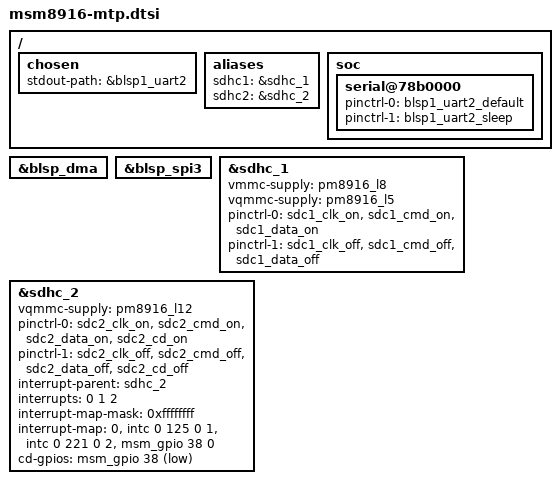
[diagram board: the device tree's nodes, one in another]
/* Copyright (c) 2014-2014, The Linux Foundation. All rights reserved.
 *
 * This program is free software; you can redistribute it and/or modify
 * it under the terms of the GNU General Public License version 2 and
 * only version 2 as published by the Free Software Foundation.
 *
 * This program is distributed in the hope that it will be useful,
 * but WITHOUT ANY WARRANTY; without even the implied warranty of
 * MERCHANTABILITY or FITNESS FOR A PARTICULAR PURPOSE.  See the
 * GNU General Public License for more details.
 */

#include "msm8916.dtsi"

/ {
	chosen {
		stdout-path = &blsp1_uart2;
	};

	aliases {
		sdhc1 = &sdhc_1; /* SDC1 eMMC slot */
		sdhc2 = &sdhc_2; /* SDC2 SD card slot */
	};

	soc {
		serial@78b0000 {
			status = "okay";
			pinctrl-names = "default", "sleep";
			pinctrl-0 = <&blsp1_uart2_default>;
			pinctrl-1 = <&blsp1_uart2_sleep>;
		};
	};
};

&blsp_dma {
	status = "okay";
};

&blsp_spi3 {
	status = "okay";
};

&sdhc_1 {
	vmmc-supply = <&pm8916_l8>;
	vqmmc-supply = <&pm8916_l5>;

	pinctrl-names = "active", "sleep";
	pinctrl-0 = <&sdc1_clk_on &sdc1_cmd_on &sdc1_data_on>;
	pinctrl-1 = <&sdc1_clk_off &sdc1_cmd_off &sdc1_data_off>;
	status = "okay";
};

&sdhc_2 {
	//vmmc-supply = <&pm8916_l11>;
	vqmmc-supply = <&pm8916_l12>;

	pinctrl-names = "active", "sleep";
	pinctrl-0 = <&sdc2_clk_on &sdc2_cmd_on &sdc2_data_on &sdc2_cd_on>;
	pinctrl-1 = <&sdc2_clk_off &sdc2_cmd_off &sdc2_data_off &sdc2_cd_off>;
	#address-cells = <0>;
	interrupt-parent = <&sdhc_2>;
	interrupts = <0 1 2>;
	#interrupt-cells = <1>;
	interrupt-map-mask = <0xffffffff>;
	interrupt-map = <0 &intc 0 125 0
			1 &intc 0 221 0
			2 &msm_gpio 38 0>;
	interrupt-names = "hc_irq", "pwr_irq", "status_irq";
	cd-gpios = <&msm_gpio 38 0x1>;

	status = "okay";
};
